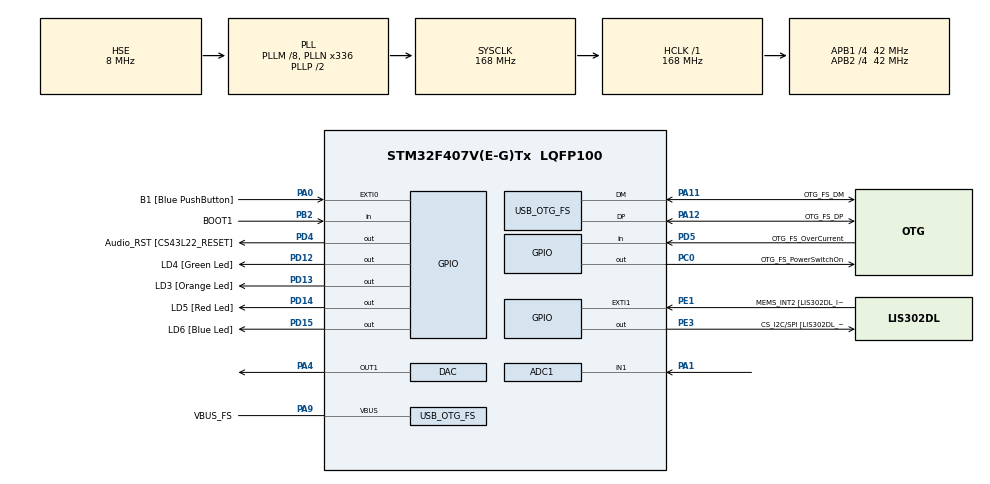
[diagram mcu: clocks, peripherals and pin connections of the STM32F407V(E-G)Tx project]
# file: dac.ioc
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PA11.GPIO_Speed=GPIO_SPEED_FREQ_LOW
PD12.GPIO_Label=LD4 [Green Led]
PH0-OSC_IN.Signal=RCC_OSC_IN
PC10.GPIO_PuPd=GPIO_NOPULL
PB10.GPIO_PuPd=GPIO_NOPULL
PA10.GPIO_PuPd=GPIO_NOPULL
PC12.Signal=I2S3_SD
PA14.GPIO_Label=SWCLK
PA6.GPIO_Label=SPI1_MISO [LIS302DL_SDO]
PB6.GPIO_Label=Audio_SCL [CS43L22_SCL]
PC15-OSC32_OUT.GPIO_Label=PC15-OSC32_OUT
RCC.SYSCLKSource=RCC_SYSCLKSOURCE_PLLCLK
PC3.GPIO_Speed=GPIO_SPEED_FREQ_LOW
PA6.GPIO_Mode=GPIO_MODE_AF_PP
PD14.GPIO_Speed=GPIO_SPEED_FREQ_LOW
Dma.DAC1.0.PeriphInc=DMA_PINC_DISABLE
PD4.Signal=GPIO_Output
RCC.APB2TimFreq_Value=84000000
PB6.Signal=I2C1_SCL
PC7.Signal=I2S3_MCK
PC3.Signal=I2S2_SD
PE1.Signal=GPXTI1
Dma.DAC1.0.Direction=DMA_MEMORY_TO_PERIPH
USB_OTG_FS.phy_itface=HCD_PHY_EMBEDDED
PB2.Signal=GPIO_Input
DAC.DAC_Trigger=DAC_TRIGGER_T2_TRGO
PD5.GPIO_Mode=GPIO_MODE_INPUT
PD14.GPIO_PuPd=GPIO_NOPULL
PB2.GPIO_PuPd=GPIO_NOPULL
ADC1.SamplingTime-0\#ChannelRegularConversion=ADC_SAMPLETIME_3CYCLES
Mcu.Package=LQFP100
PB9.Signal=I2C1_SDA
TIM2.Prescaler=84-1
Dma.DAC1.0.PeriphDataAlignment=DMA_PDATAALIGN_WORD
PD12.Signal=GPIO_Output
PB9.GPIO_PuPd=GPIO_NOPULL
PA10.Signal=USB_OTG_FS_ID
RCC.APB2CLKDivider=RCC_HCLK_DIV4
RCC.APB1TimFreq_Value=84000000
PC12.GPIO_PuPd=GPIO_NOPULL
PA6.GPIO_Speed=GPIO_SPEED_FREQ_LOW
PA12.GPIO_PuPd=GPIO_NOPULL
PD15.Signal=GPIO_Output
PC0.PinState=GPIO_PIN_SET
ADC1.Rank-0\#ChannelRegularConversion=1
PA9.GPIO_Label=VBUS_FS
PB6.GPIO_PuPd=GPIO_NOPULL
PA11.GPIO_Label=OTG_FS_DM
PE1.GPIO_PuPd=GPIO_NOPULL
PC0.Signal=GPIO_Output
RCC.APB1CLKDivider=RCC_HCLK_DIV4
PC14-OSC32_IN.Signal=RCC_OSC32_IN
PA0-WKUP.GPIO_ModeDefaultEXTI=GPIO_MODE_EVT_RISING
PA0-WKUP.GPIO_Label=B1 [Blue PushButton]
PA0-WKUP.Signal=GPXTI0
Dma.DAC1.0.MemDataAlignment=DMA_MDATAALIGN_WORD
USB_HOST0.BSP.STBoard=false
PC10.GPIO_Mode=GPIO_MODE_AF_PP
PB10.GPIO_Mode=GPIO_MODE_AF_PP
PA9.Signal=USB_OTG_FS_VBUS
PC7.GPIO_PuPd=GPIO_NOPULL
PB10.Signal=I2S2_CK
PE1.GPIO_Label=MEMS_INT2 [LIS302DL_INT2]
USB_HOST.VirtualModeFS=Cdc
PA7.GPIO_Speed=GPIO_SPEED_FREQ_LOW
PB2.GPIO_Mode=GPIO_MODE_INPUT
PD4.GPIO_Speed=GPIO_SPEED_FREQ_LOW
PE3.GPIO_PuPd=GPIO_NOPULL
PH1-OSC_OUT.GPIO_Label=PH1-OSC_OUT
TIM2.Period=100-1
PA13.Mode=Serial_Wire
PC7.GPIO_Label=I2S3_MCK [CS43L22_MCLK]
PA4.Signal=COMP_DAC1_group
PC12.GPIO_Mode=GPIO_MODE_AF_PP
ADC1.master=1
PE3.GPIO_Speed=GPIO_SPEED_FREQ_LOW
PC12.GPIO_Label=I2S3_SD [CS43L22_SDIN]
PA11.Signal=USB_OTG_FS_DM
ProjectManager.HeapSize=0x200
NVIC.PriorityGroup=NVIC_PRIORITYGROUP_0
PE3.Signal=GPIO_Output
PC3.GPIO_Label=PDM_OUT [MP45DT02_DOUT]
PA0-WKUP.GPIO_PuPd=GPIO_NOPULL
PB6.GPIO_Speed=GPIO_SPEED_FREQ_LOW
USB_HOST0.BSP.mode=Output
Mcu.Family=STM32F4
PC3.GPIO_Mode=GPIO_MODE_AF_PP
RCC.CortexFreq_Value=168000000
PB10.GPIO_Speed=GPIO_SPEED_FREQ_LOW
PB6.GPIO_Mode=GPIO_MODE_AF_OD
PD15.GPIO_Speed=GPIO_SPEED_FREQ_LOW
PC10.Signal=I2S3_CK
PA7.GPIO_Mode=GPIO_MODE_AF_PP
PC0.GPIO_Label=OTG_FS_PowerSwitchOn
PA11.Mode=Host_Only
PC10.GPIO_Speed=GPIO_SPEED_FREQ_LOW
PA11.GPIO_PuPd=GPIO_NOPULL
ProjectManager.StackSize=0x400
PD13.Signal=GPIO_Output
PA12.Signal=USB_OTG_FS_DP
RCC.HCLKFreq_Value=168000000
USB_HOST0.BSP.ip=GPIO
RCC.AHBFreq_Value=168000000
PH0-OSC_IN.Mode=HSE-External-Oscillator
PH0-OSC_IN.GPIO_Label=PH0-OSC_IN
PA9.GPIO_Mode=GPIO_MODE_INPUT
ADC1.Channel-0\#ChannelRegularConversion=ADC_CHANNEL_1
RCC.HSE_VALUE=8000000
PA6.GPIO_PuPd=GPIO_NOPULL
Dma.DAC1.0.Priority=DMA_PRIORITY_LOW
PC14-OSC32_IN.Mode=LSE-External-Oscillator
Dma.DAC1.0.FIFOMode=DMA_FIFOMODE_DISABLE
PA14.Mode=Serial_Wire
PA10.GPIO_Label=OTG_FS_ID
PC7.GPIO_Mode=GPIO_MODE_AF_PP
USB_HOST0.BSP.i2creg=0
PH1-OSC_OUT.Mode=HSE-External-Oscillator
USB_HOST0.BSP.i2caddr=0
PD13.GPIO_Label=LD3 [Orange Led]
PA6.Signal=SPI1_MISO
USB_HOST.USBH_HandleTypeDef-CDC_FS=hUsbHostFS
PD5.GPIO_Label=OTG_FS_OverCurrent
NVIC.OTG_FS_IRQn=true\:0\:0\:false\:false\:true\:true\:true
Dma.DAC1.0.Mode=DMA_CIRCULAR
PD15.GPIO_PuPd=GPIO_NOPULL
USB_OTG_FS.VirtualMode=Host_Only
PA10.GPIO_Speed=GPIO_SPEED_FREQ_LOW
TIM2.TIM_MasterOutputTrigger=TIM_TRGO_UPDATE
USB_HOST0.BSP.name=Drive_VBUS_FS
SH.ADCx_IN1.0=ADC1_IN1,IN1
PB9.GPIO_Speed=GPIO_SPEED_FREQ_LOW
PC14-OSC32_IN.GPIO_Label=PC14-OSC32_IN
PC0.GPIO_PuPd=GPIO_NOPULL
Dma.Request0=DAC1
PA12.GPIO_Speed=GPIO_SPEED_FREQ_LOW
PB3.GPIO_Label=SWO
SH.COMP_DAC1_group.0=DAC_OUT1,DAC_OUT1
PC15-OSC32_OUT.Mode=LSE-External-Oscillator
PD12.GPIO_Speed=GPIO_SPEED_FREQ_LOW
PD15.GPIO_Label=LD6 [Blue Led]
Dma.DAC1.0.Instance=DMA1_Stream5
PB9.GPIO_Label=Audio_SDA [CS43L22_SDA]
PC10.GPIO_Label=I2S3_SCK [CS43L22_SCLK]
USB_HOST0.BSP.solution=PC0
USB_HOST.BSP.number=1
PD5.Signal=GPIO_Input
PE1.GPIO_ModeDefaultEXTI=GPIO_MODE_EVT_RISING
PA9.GPIO_PuPd=GPIO_NOPULL
PA12.GPIO_Label=OTG_FS_DP
PA10.GPIO_Mode=GPIO_MODE_AF_PP
PA13.Signal=SYS_JTMS-SWDIO
PD4.GPIO_PuPd=GPIO_NOPULL
PA9.Mode=Activate_VBUS
PC0.GPIO_Speed=GPIO_SPEED_FREQ_LOW
ProjectManager.TargetToolchain=STM32CubeIDE
PB10.GPIO_Label=CLK_IN [MP45DT02_CLK]
NVIC.DMA1_Stream5_IRQn=true\:0\:0\:false\:false\:true\:false\:true
PC15-OSC32_OUT.Signal=RCC_OSC32_OUT
PA1.Signal=ADCx_IN1
PA7.GPIO_PuPd=GPIO_NOPULL
board=STM32F407G-DISC1
PD13.GPIO_Speed=GPIO_SPEED_FREQ_LOW
PC7.GPIO_Speed=GPIO_SPEED_FREQ_LOW
RCC.VCOOutputFreq_Value=336000000
PB9.GPIO_Mode=GPIO_MODE_AF_OD
PA12.GPIO_Mode=GPIO_MODE_AF_PP
RCC.APB2Freq_Value=42000000
USB_HOST0.BSP.api=Unknown
VP_TIM2_VS_ClockSourceINT.Mode=Internal
PD4.GPIO_Label=Audio_RST [CS43L22_RESET]
PH1-OSC_OUT.Signal=RCC_OSC_OUT
PD13.GPIO_PuPd=GPIO_NOPULL
PD5.GPIO_PuPd=GPIO_NOPULL
PD14.GPIO_Label=LD5 [Red Led]
Mcu.Name=STM32F407V(E-G)Tx
PA13.GPIO_Label=SWDIO
PD14.Signal=GPIO_Output
RCC.48MHZClocksFreq_Value=48000000
PB3.Signal=SYS_JTDO-SWO
RCC.SYSCLKFreq_VALUE=168000000
PA7.GPIO_Label=SPI1_MOSI [LIS302DL_SDA/SDI/SDO]
PA12.Mode=Host_Only
Dma.DAC1.0.MemInc=DMA_MINC_ENABLE
VP_USB_HOST_VS_USB_HOST_CDC_FS.Mode=CDC_FS
PA14.Signal=SYS_JTCK-SWCLK
PB2.GPIO_Label=BOOT1
RCC.HSI_VALUE=16000000
RCC.PLLQ=7
ADC1.NbrOfConversionFlag=1
RCC.PLLM=8
RCC.PLLN=336
PE3.GPIO_Label=CS_I2C/SPI [LIS302DL_CS_I2C/SPI]
PA11.GPIO_Mode=GPIO_MODE_AF_PP
RCC.APB1Freq_Value=42000000
PC12.GPIO_Speed=GPIO_SPEED_FREQ_LOW
PC3.GPIO_PuPd=GPIO_NOPULL
PD12.GPIO_PuPd=GPIO_NOPULL
PA7.Signal=SPI1_MOSI
USB_HOST0.BSP.instance=PC0

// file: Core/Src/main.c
/* USER CODE BEGIN Header */
/**
  ******************************************************************************
  * @file           : main.c
  * @brief          : Main program body
  ******************************************************************************
  * @attention
  *
  * <h2><center>&copy; Copyright (c) 2022 STMicroelectronics.
  * All rights reserved.</center></h2>
  *
  * This software component is licensed by ST under Ultimate Liberty license
  * SLA0044, the "License"; You may not use this file except in compliance with
  * the License. You may obtain a copy of the License at:
  *                             www.st.com/SLA0044
  *
  ******************************************************************************
  */
/* USER CODE END Header */
#include "main.h"
#include "usb_host.h"

/* USER CODE BEGIN Includes */
#include <math.h>
/* USER CODE END Includes */

ADC_HandleTypeDef hadc1;

DAC_HandleTypeDef hdac;
DMA_HandleTypeDef hdma_dac1;

TIM_HandleTypeDef htim2;

void SystemClock_Config(void);
static void MX_GPIO_Init(void);
static void MX_DMA_Init(void);
static void MX_ADC1_Init(void);
static void MX_DAC_Init(void);
static void MX_TIM2_Init(void);
void MX_USB_HOST_Process(void);

/* USER CODE BEGIN 0 */
uint32_t sine_val[100];

#define PI 3.1415926

void calcsin ()
{
	for (int i=0; i<100; i++)
	{
		sine_val[i] = ((sin(i*2*PI/100) + 1)*(4096/2));
	}
}

/* USER CODE END 0 */

int main(void)
{

  /* MCU Configuration--------------------------------------------------------*/

  /* Reset of all peripherals, Initializes the Flash interface and the Systick. */
  HAL_Init();

  /* Configure the system clock */
  SystemClock_Config();

  /* Initialize all configured peripherals */
  MX_GPIO_Init();
  MX_DMA_Init();
  MX_USB_HOST_Init();
  MX_ADC1_Init();
  MX_DAC_Init();
  MX_TIM2_Init();
  /* USER CODE BEGIN 2 */
  HAL_TIM_Base_Start(&htim2);

  calcsin();

  HAL_DAC_Start_DMA(&hdac, DAC1_CHANNEL_1, sine_val, 100, DAC_ALIGN_12B_R);

  /* USER CODE END 2 */

  /* Infinite loop */
  while (1)
  {
    MX_USB_HOST_Process();

  }
}

void SystemClock_Config(void)
{
  RCC_OscInitTypeDef RCC_OscInitStruct = {0};
  RCC_ClkInitTypeDef RCC_ClkInitStruct = {0};

  /** Configure the main internal regulator output voltage
  */
  __HAL_RCC_PWR_CLK_ENABLE();
  __HAL_PWR_VOLTAGESCALING_CONFIG(PWR_REGULATOR_VOLTAGE_SCALE1);
  /** Initializes the RCC Oscillators according to the specified parameters
  * in the RCC_OscInitTypeDef structure.
  */
  RCC_OscInitStruct.OscillatorType = RCC_OSCILLATORTYPE_HSE;
  RCC_OscInitStruct.HSEState = RCC_HSE_ON;
  RCC_OscInitStruct.PLL.PLLState = RCC_PLL_ON;
  RCC_OscInitStruct.PLL.PLLSource = RCC_PLLSOURCE_HSE;
  RCC_OscInitStruct.PLL.PLLM = 8;
  RCC_OscInitStruct.PLL.PLLN = 336;
  RCC_OscInitStruct.PLL.PLLP = RCC_PLLP_DIV2;
  RCC_OscInitStruct.PLL.PLLQ = 7;
  if (HAL_RCC_OscConfig(&RCC_OscInitStruct) != HAL_OK)
  {
    Error_Handler();
  }
  /** Initializes the CPU, AHB and APB buses clocks
  */
  RCC_ClkInitStruct.ClockType = RCC_CLOCKTYPE_HCLK|RCC_CLOCKTYPE_SYSCLK
                              |RCC_CLOCKTYPE_PCLK1|RCC_CLOCKTYPE_PCLK2;
  RCC_ClkInitStruct.SYSCLKSource = RCC_SYSCLKSOURCE_PLLCLK;
  RCC_ClkInitStruct.AHBCLKDivider = RCC_SYSCLK_DIV1;
  RCC_ClkInitStruct.APB1CLKDivider = RCC_HCLK_DIV4;
  RCC_ClkInitStruct.APB2CLKDivider = RCC_HCLK_DIV4;

  if (HAL_RCC_ClockConfig(&RCC_ClkInitStruct, FLASH_LATENCY_5) != HAL_OK)
  {
    Error_Handler();
  }
}

static void MX_ADC1_Init(void)
{

  ADC_ChannelConfTypeDef sConfig = {0};

  /** Configure the global features of the ADC (Clock, Resolution, Data Alignment and number of conversion)
  */
  hadc1.Instance = ADC1;
  hadc1.Init.ClockPrescaler = ADC_CLOCK_SYNC_PCLK_DIV2;
  hadc1.Init.Resolution = ADC_RESOLUTION_12B;
  hadc1.Init.ScanConvMode = DISABLE;
  hadc1.Init.ContinuousConvMode = DISABLE;
  hadc1.Init.DiscontinuousConvMode = DISABLE;
  hadc1.Init.ExternalTrigConvEdge = ADC_EXTERNALTRIGCONVEDGE_NONE;
  hadc1.Init.ExternalTrigConv = ADC_SOFTWARE_START;
  hadc1.Init.DataAlign = ADC_DATAALIGN_RIGHT;
  hadc1.Init.NbrOfConversion = 1;
  hadc1.Init.DMAContinuousRequests = DISABLE;
  hadc1.Init.EOCSelection = ADC_EOC_SINGLE_CONV;
  if (HAL_ADC_Init(&hadc1) != HAL_OK)
  {
    Error_Handler();
  }
  /** Configure for the selected ADC regular channel its corresponding rank in the sequencer and its sample time.
  */
  sConfig.Channel = ADC_CHANNEL_1;
  sConfig.Rank = 1;
  sConfig.SamplingTime = ADC_SAMPLETIME_3CYCLES;
  if (HAL_ADC_ConfigChannel(&hadc1, &sConfig) != HAL_OK)
  {
    Error_Handler();
  }

}

static void MX_DAC_Init(void)
{

  DAC_ChannelConfTypeDef sConfig = {0};

  /** DAC Initialization
  */
  hdac.Instance = DAC;
  if (HAL_DAC_Init(&hdac) != HAL_OK)
  {
    Error_Handler();
  }
  /** DAC channel OUT1 config
  */
  sConfig.DAC_Trigger = DAC_TRIGGER_T2_TRGO;
  sConfig.DAC_OutputBuffer = DAC_OUTPUTBUFFER_ENABLE;
  if (HAL_DAC_ConfigChannel(&hdac, &sConfig, DAC_CHANNEL_1) != HAL_OK)
  {
    Error_Handler();
  }

}

static void MX_TIM2_Init(void)
{

  TIM_ClockConfigTypeDef sClockSourceConfig = {0};
  TIM_MasterConfigTypeDef sMasterConfig = {0};

  htim2.Instance = TIM2;
  htim2.Init.Prescaler = 84-1;
  htim2.Init.CounterMode = TIM_COUNTERMODE_UP;
  htim2.Init.Period = 100-1;
  htim2.Init.ClockDivision = TIM_CLOCKDIVISION_DIV1;
  htim2.Init.AutoReloadPreload = TIM_AUTORELOAD_PRELOAD_DISABLE;
  if (HAL_TIM_Base_Init(&htim2) != HAL_OK)
  {
    Error_Handler();
  }
  sClockSourceConfig.ClockSource = TIM_CLOCKSOURCE_INTERNAL;
  if (HAL_TIM_ConfigClockSource(&htim2, &sClockSourceConfig) != HAL_OK)
  {
    Error_Handler();
  }
  sMasterConfig.MasterOutputTrigger = TIM_TRGO_UPDATE;
  sMasterConfig.MasterSlaveMode = TIM_MASTERSLAVEMODE_DISABLE;
  if (HAL_TIMEx_MasterConfigSynchronization(&htim2, &sMasterConfig) != HAL_OK)
  {
    Error_Handler();
  }

}

static void MX_DMA_Init(void)
{

  /* DMA controller clock enable */
  __HAL_RCC_DMA1_CLK_ENABLE();

  /* DMA interrupt init */
  /* DMA1_Stream5_IRQn interrupt configuration */
  HAL_NVIC_SetPriority(DMA1_Stream5_IRQn, 0, 0);
  HAL_NVIC_EnableIRQ(DMA1_Stream5_IRQn);

}

static void MX_GPIO_Init(void)
{
  GPIO_InitTypeDef GPIO_InitStruct = {0};

  /* GPIO Ports Clock Enable */
  __HAL_RCC_GPIOE_CLK_ENABLE();
  __HAL_RCC_GPIOC_CLK_ENABLE();
  __HAL_RCC_GPIOH_CLK_ENABLE();
  __HAL_RCC_GPIOA_CLK_ENABLE();
  __HAL_RCC_GPIOB_CLK_ENABLE();
  __HAL_RCC_GPIOD_CLK_ENABLE();

  /*Configure GPIO pin Output Level */
  HAL_GPIO_WritePin(CS_I2C_SPI_GPIO_Port, CS_I2C_SPI_Pin, GPIO_PIN_RESET);

  /*Configure GPIO pin Output Level */
  HAL_GPIO_WritePin(OTG_FS_PowerSwitchOn_GPIO_Port, OTG_FS_PowerSwitchOn_Pin, GPIO_PIN_SET);

  /*Configure GPIO pin Output Level */
  HAL_GPIO_WritePin(GPIOD, LD4_Pin|LD3_Pin|LD5_Pin|LD6_Pin
                          |Audio_RST_Pin, GPIO_PIN_RESET);

  /*Configure GPIO pin : CS_I2C_SPI_Pin */
  GPIO_InitStruct.Pin = CS_I2C_SPI_Pin;
  GPIO_InitStruct.Mode = GPIO_MODE_OUTPUT_PP;
  GPIO_InitStruct.Pull = GPIO_NOPULL;
  GPIO_InitStruct.Speed = GPIO_SPEED_FREQ_LOW;
  HAL_GPIO_Init(CS_I2C_SPI_GPIO_Port, &GPIO_InitStruct);

  /*Configure GPIO pin : OTG_FS_PowerSwitchOn_Pin */
  GPIO_InitStruct.Pin = OTG_FS_PowerSwitchOn_Pin;
  GPIO_InitStruct.Mode = GPIO_MODE_OUTPUT_PP;
  GPIO_InitStruct.Pull = GPIO_NOPULL;
  GPIO_InitStruct.Speed = GPIO_SPEED_FREQ_LOW;
  HAL_GPIO_Init(OTG_FS_PowerSwitchOn_GPIO_Port, &GPIO_InitStruct);

  /*Configure GPIO pin : PDM_OUT_Pin */
  GPIO_InitStruct.Pin = PDM_OUT_Pin;
  GPIO_InitStruct.Mode = GPIO_MODE_AF_PP;
  GPIO_InitStruct.Pull = GPIO_NOPULL;
  GPIO_InitStruct.Speed = GPIO_SPEED_FREQ_LOW;
  GPIO_InitStruct.Alternate = GPIO_AF5_SPI2;
  HAL_GPIO_Init(PDM_OUT_GPIO_Port, &GPIO_InitStruct);

  /*Configure GPIO pin : B1_Pin */
  GPIO_InitStruct.Pin = B1_Pin;
  GPIO_InitStruct.Mode = GPIO_MODE_EVT_RISING;
  GPIO_InitStruct.Pull = GPIO_NOPULL;
  HAL_GPIO_Init(B1_GPIO_Port, &GPIO_InitStruct);

  /*Configure GPIO pins : SPI1_MISO_Pin SPI1_MOSI_Pin */
  GPIO_InitStruct.Pin = SPI1_MISO_Pin|SPI1_MOSI_Pin;
  GPIO_InitStruct.Mode = GPIO_MODE_AF_PP;
  GPIO_InitStruct.Pull = GPIO_NOPULL;
  GPIO_InitStruct.Speed = GPIO_SPEED_FREQ_LOW;
  GPIO_InitStruct.Alternate = GPIO_AF5_SPI1;
  HAL_GPIO_Init(GPIOA, &GPIO_InitStruct);

  /*Configure GPIO pin : BOOT1_Pin */
  GPIO_InitStruct.Pin = BOOT1_Pin;
  GPIO_InitStruct.Mode = GPIO_MODE_INPUT;
  GPIO_InitStruct.Pull = GPIO_NOPULL;
  HAL_GPIO_Init(BOOT1_GPIO_Port, &GPIO_InitStruct);

  /*Configure GPIO pin : CLK_IN_Pin */
  GPIO_InitStruct.Pin = CLK_IN_Pin;
  GPIO_InitStruct.Mode = GPIO_MODE_AF_PP;
  GPIO_InitStruct.Pull = GPIO_NOPULL;
  GPIO_InitStruct.Speed = GPIO_SPEED_FREQ_LOW;
  GPIO_InitStruct.Alternate = GPIO_AF5_SPI2;
  HAL_GPIO_Init(CLK_IN_GPIO_Port, &GPIO_InitStruct);

  /*Configure GPIO pins : LD4_Pin LD3_Pin LD5_Pin LD6_Pin
                           Audio_RST_Pin */
  GPIO_InitStruct.Pin = LD4_Pin|LD3_Pin|LD5_Pin|LD6_Pin
                          |Audio_RST_Pin;
  GPIO_InitStruct.Mode = GPIO_MODE_OUTPUT_PP;
  GPIO_InitStruct.Pull = GPIO_NOPULL;
  GPIO_InitStruct.Speed = GPIO_SPEED_FREQ_LOW;
  HAL_GPIO_Init(GPIOD, &GPIO_InitStruct);

  /*Configure GPIO pins : I2S3_MCK_Pin I2S3_SCK_Pin I2S3_SD_Pin */
  GPIO_InitStruct.Pin = I2S3_MCK_Pin|I2S3_SCK_Pin|I2S3_SD_Pin;
  GPIO_InitStruct.Mode = GPIO_MODE_AF_PP;
  GPIO_InitStruct.Pull = GPIO_NOPULL;
  GPIO_InitStruct.Speed = GPIO_SPEED_FREQ_LOW;
  GPIO_InitStruct.Alternate = GPIO_AF6_SPI3;
  HAL_GPIO_Init(GPIOC, &GPIO_InitStruct);

  /*Configure GPIO pin : OTG_FS_OverCurrent_Pin */
  GPIO_InitStruct.Pin = OTG_FS_OverCurrent_Pin;
  GPIO_InitStruct.Mode = GPIO_MODE_INPUT;
  GPIO_InitStruct.Pull = GPIO_NOPULL;
  HAL_GPIO_Init(OTG_FS_OverCurrent_GPIO_Port, &GPIO_InitStruct);

  /*Configure GPIO pins : Audio_SCL_Pin Audio_SDA_Pin */
  GPIO_InitStruct.Pin = Audio_SCL_Pin|Audio_SDA_Pin;
  GPIO_InitStruct.Mode = GPIO_MODE_AF_OD;
  GPIO_InitStruct.Pull = GPIO_PULLUP;
  GPIO_InitStruct.Speed = GPIO_SPEED_FREQ_LOW;
  GPIO_InitStruct.Alternate = GPIO_AF4_I2C1;
  HAL_GPIO_Init(GPIOB, &GPIO_InitStruct);

  /*Configure GPIO pin : MEMS_INT2_Pin */
  GPIO_InitStruct.Pin = MEMS_INT2_Pin;
  GPIO_InitStruct.Mode = GPIO_MODE_EVT_RISING;
  GPIO_InitStruct.Pull = GPIO_NOPULL;
  HAL_GPIO_Init(MEMS_INT2_GPIO_Port, &GPIO_InitStruct);

}

void Error_Handler(void)
{
  __disable_irq();
  while (1)
  {
  }
}

/************************ (C) COPYRIGHT STMicroelectronics *****END OF FILE****/
